# PIC32MK0128MCA048 device description
Architecture: MIPS; Family: PIC32MK; Series: PIC32MK
Registers are 32-bit, read-write, no defined reset value unless marked. A register's access mark holds for its fields unless they carry their own. Offsets are from the block's base; [hi:lo] are bit positions; 'fields as' and 'values as' point back to an identical list.

## GPIO
Instances: GPIO 0x1f860000 in periph_pb4_std
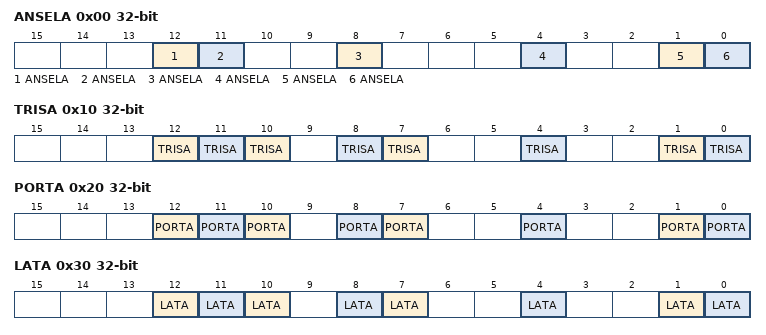
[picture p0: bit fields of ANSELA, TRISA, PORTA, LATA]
0x00 ANSELA
  [12] ANSELA, [11] ANSELA, [8] ANSELA, [4] ANSELA, [1] ANSELA, [0] ANSELA
0x10 TRISA
  [12] TRISA, [11] TRISA, [10] TRISA, [8] TRISA, [7] TRISA, [4] TRISA, [1] TRISA, [0] TRISA
0x20 PORTA
  [12] PORTA, [11] PORTA, [10] PORTA, [8] PORTA, [7] PORTA, [4] PORTA, [1] PORTA, [0] PORTA
0x30 LATA
  [12] LATA, [11] LATA, [10] LATA, [8] LATA, [7] LATA, [4] LATA, [1] LATA, [0] LATA
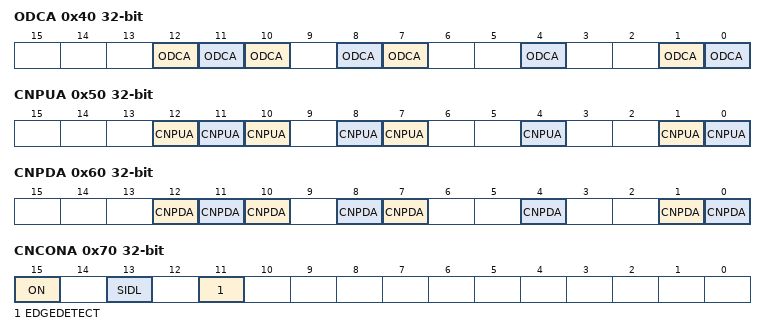
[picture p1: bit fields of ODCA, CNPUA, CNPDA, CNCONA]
0x40 ODCA
  [12] ODCA, [11] ODCA, [10] ODCA, [8] ODCA, [7] ODCA, [4] ODCA, [1] ODCA, [0] ODCA
0x50 CNPUA
  [12] CNPUA, [11] CNPUA, [10] CNPUA, [8] CNPUA, [7] CNPUA, [4] CNPUA, [1] CNPUA, [0] CNPUA
0x60 CNPDA
  [12] CNPDA, [11] CNPDA, [10] CNPDA, [8] CNPDA, [7] CNPDA, [4] CNPDA, [1] CNPDA, [0] CNPDA
0x70 CNCONA — Change Notice control for PORTx Register
  [15] ON — Change Notice Control ON bit
    1=CN is enabled; 0=CN is disabled
  [13] SIDL
  [11] EDGEDETECT — Change Notification Style bit
    1=Edge Style. Detect edge transitions (CNFx used for CN Event).; 0=Mismatch Style. Detect change from last PORTx read (CNSTATx used for CN Event).
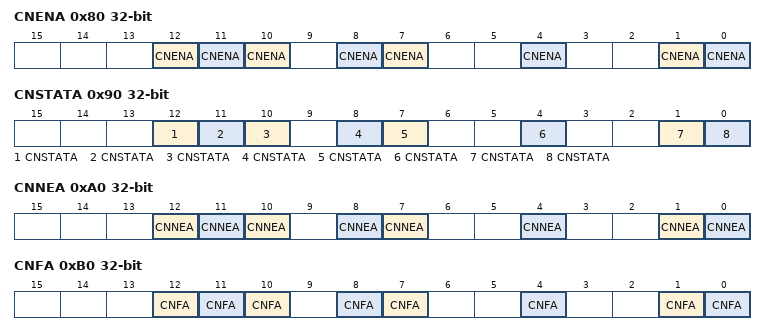
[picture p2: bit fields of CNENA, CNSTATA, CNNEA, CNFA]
0x80 CNENA
  [12] CNENA, [11] CNENA, [10] CNENA, [8] CNENA, [7] CNENA, [4] CNENA, [1] CNENA, [0] CNENA
0x90 CNSTATA
  [12] CNSTATA, [11] CNSTATA, [10] CNSTATA, [8] CNSTATA, [7] CNSTATA, [4] CNSTATA, [1] CNSTATA, [0] CNSTATA
0xA0 CNNEA
  [12] CNNEA, [11] CNNEA, [10] CNNEA, [8] CNNEA, [7] CNNEA, [4] CNNEA, [1] CNNEA, [0] CNNEA
0xB0 CNFA
  [12] CNFA, [11] CNFA, [10] CNFA, [8] CNFA, [7] CNFA, [4] CNFA, [1] CNFA, [0] CNFA
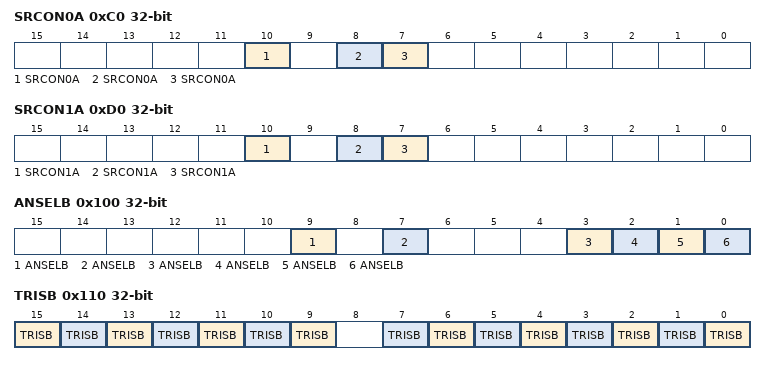
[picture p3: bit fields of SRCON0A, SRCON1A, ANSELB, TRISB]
0xC0 SRCON0A
  [10] SRCON0A, [8] SRCON0A, [7] SRCON0A
0xD0 SRCON1A
  [10] SRCON1A, [8] SRCON1A, [7] SRCON1A
0x100 ANSELB
  [9] ANSELB, [7] ANSELB, [3] ANSELB, [2] ANSELB, [1] ANSELB, [0] ANSELB
0x110 TRISB
  [15] TRISB, [14] TRISB, [13] TRISB, [12] TRISB, [11] TRISB, [10] TRISB, [9] TRISB, [7] TRISB, [6] TRISB, [5] TRISB, [4] TRISB, [3] TRISB, [2] TRISB, [1] TRISB, [0] TRISB
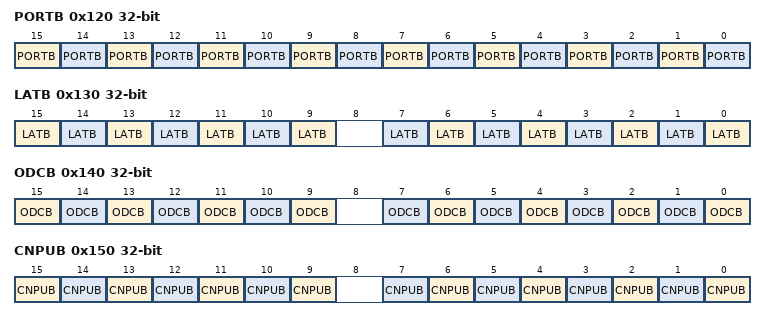
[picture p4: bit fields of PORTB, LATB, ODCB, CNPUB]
0x120 PORTB
  [15] PORTB, [14] PORTB, [13] PORTB, [12] PORTB, [11] PORTB, [10] PORTB, [9] PORTB, [8] PORTB, [7] PORTB, [6] PORTB, [5] PORTB, [4] PORTB, [3] PORTB, [2] PORTB, [1] PORTB, [0] PORTB
0x130 LATB
  [15] LATB, [14] LATB, [13] LATB, [12] LATB, [11] LATB, [10] LATB, [9] LATB, [7] LATB, [6] LATB, [5] LATB, [4] LATB, [3] LATB, [2] LATB, [1] LATB, [0] LATB
0x140 ODCB
  [15] ODCB, [14] ODCB, [13] ODCB, [12] ODCB, [11] ODCB, [10] ODCB, [9] ODCB, [7] ODCB, [6] ODCB, [5] ODCB, [4] ODCB, [3] ODCB, [2] ODCB, [1] ODCB, [0] ODCB
0x150 CNPUB
  [15] CNPUB, [14] CNPUB, [13] CNPUB, [12] CNPUB, [11] CNPUB, [10] CNPUB, [9] CNPUB, [7] CNPUB, [6] CNPUB, [5] CNPUB, [4] CNPUB, [3] CNPUB, [2] CNPUB, [1] CNPUB, [0] CNPUB
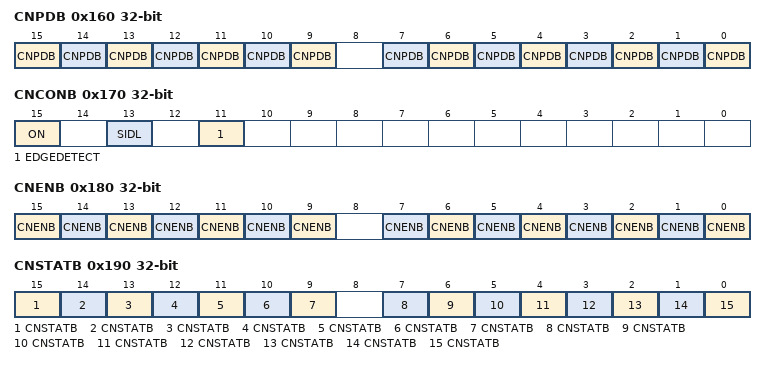
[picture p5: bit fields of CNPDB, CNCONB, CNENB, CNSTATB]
0x160 CNPDB
  [15] CNPDB, [14] CNPDB, [13] CNPDB, [12] CNPDB, [11] CNPDB, [10] CNPDB, [9] CNPDB, [7] CNPDB, [6] CNPDB, [5] CNPDB, [4] CNPDB, [3] CNPDB, [2] CNPDB, [1] CNPDB, [0] CNPDB
0x170 CNCONB — Change Notice control for PORTx Register
  fields as CNCONA
0x180 CNENB
  [15] CNENB, [14] CNENB, [13] CNENB, [12] CNENB, [11] CNENB, [10] CNENB, [9] CNENB, [7] CNENB, [6] CNENB, [5] CNENB, [4] CNENB, [3] CNENB, [2] CNENB, [1] CNENB, [0] CNENB
0x190 CNSTATB
  [15] CNSTATB, [14] CNSTATB, [13] CNSTATB, [12] CNSTATB, [11] CNSTATB, [10] CNSTATB, [9] CNSTATB, [7] CNSTATB, [6] CNSTATB, [5] CNSTATB, [4] CNSTATB, [3] CNSTATB, [2] CNSTATB, [1] CNSTATB, [0] CNSTATB
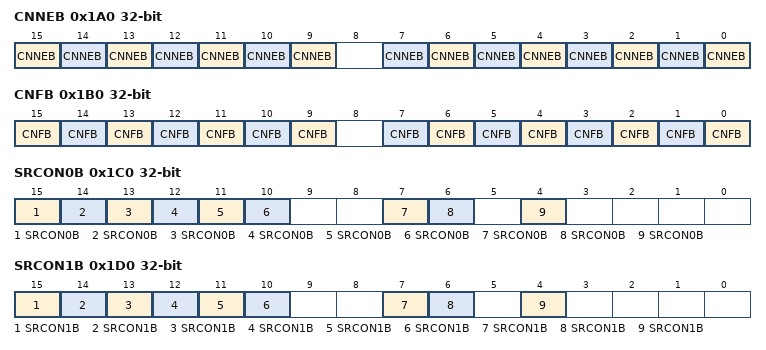
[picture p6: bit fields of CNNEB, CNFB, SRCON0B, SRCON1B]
0x1A0 CNNEB
  [15] CNNEB, [14] CNNEB, [13] CNNEB, [12] CNNEB, [11] CNNEB, [10] CNNEB, [9] CNNEB, [7] CNNEB, [6] CNNEB, [5] CNNEB, [4] CNNEB, [3] CNNEB, [2] CNNEB, [1] CNNEB, [0] CNNEB
0x1B0 CNFB
  [15] CNFB, [14] CNFB, [13] CNFB, [12] CNFB, [11] CNFB, [10] CNFB, [9] CNFB, [7] CNFB, [6] CNFB, [5] CNFB, [4] CNFB, [3] CNFB, [2] CNFB, [1] CNFB, [0] CNFB
0x1C0 SRCON0B
  [15] SRCON0B, [14] SRCON0B, [13] SRCON0B, [12] SRCON0B, [11] SRCON0B, [10] SRCON0B, [7] SRCON0B, [6] SRCON0B, [4] SRCON0B
0x1D0 SRCON1B
  [15] SRCON1B, [14] SRCON1B, [13] SRCON1B, [12] SRCON1B, [11] SRCON1B, [10] SRCON1B, [7] SRCON1B, [6] SRCON1B, [4] SRCON1B
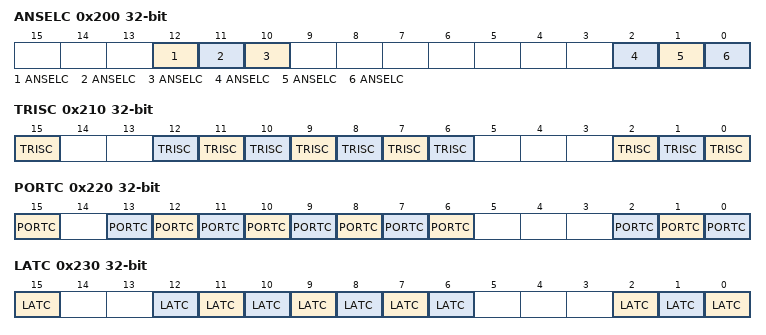
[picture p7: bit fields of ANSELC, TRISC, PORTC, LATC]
0x200 ANSELC
  [12] ANSELC, [11] ANSELC, [10] ANSELC, [2] ANSELC, [1] ANSELC, [0] ANSELC
0x210 TRISC
  [15] TRISC, [12] TRISC, [11] TRISC, [10] TRISC, [9] TRISC, [8] TRISC, [7] TRISC, [6] TRISC, [2] TRISC, [1] TRISC, [0] TRISC
0x220 PORTC
  [15] PORTC, [13] PORTC, [12] PORTC, [11] PORTC, [10] PORTC, [9] PORTC, [8] PORTC, [7] PORTC, [6] PORTC, [2] PORTC, [1] PORTC, [0] PORTC
0x230 LATC
  [15] LATC, [12] LATC, [11] LATC, [10] LATC, [9] LATC, [8] LATC, [7] LATC, [6] LATC, [2] LATC, [1] LATC, [0] LATC
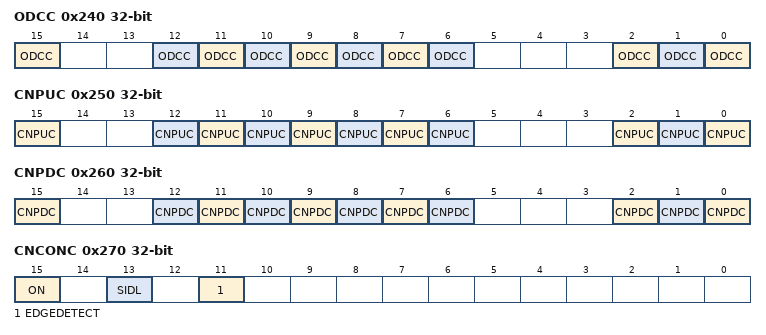
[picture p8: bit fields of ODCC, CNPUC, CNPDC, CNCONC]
0x240 ODCC
  [15] ODCC, [12] ODCC, [11] ODCC, [10] ODCC, [9] ODCC, [8] ODCC, [7] ODCC, [6] ODCC, [2] ODCC, [1] ODCC, [0] ODCC
0x250 CNPUC
  [15] CNPUC, [12] CNPUC, [11] CNPUC, [10] CNPUC, [9] CNPUC, [8] CNPUC, [7] CNPUC, [6] CNPUC, [2] CNPUC, [1] CNPUC, [0] CNPUC
0x260 CNPDC
  [15] CNPDC, [12] CNPDC, [11] CNPDC, [10] CNPDC, [9] CNPDC, [8] CNPDC, [7] CNPDC, [6] CNPDC, [2] CNPDC, [1] CNPDC, [0] CNPDC
0x270 CNCONC — Change Notice control for PORTx Register
  fields as CNCONA
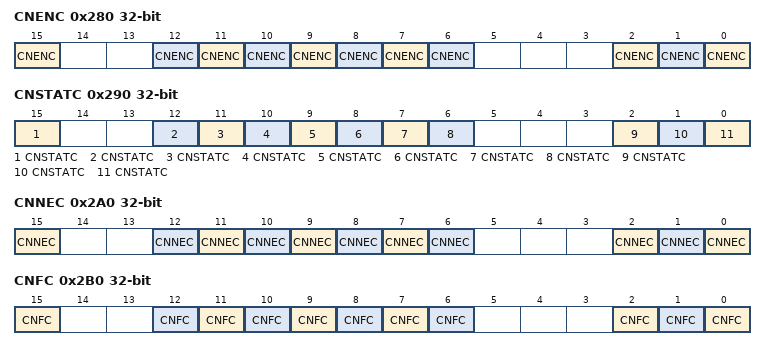
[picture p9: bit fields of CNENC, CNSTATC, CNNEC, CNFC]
0x280 CNENC
  [15] CNENC, [12] CNENC, [11] CNENC, [10] CNENC, [9] CNENC, [8] CNENC, [7] CNENC, [6] CNENC, [2] CNENC, [1] CNENC, [0] CNENC
0x290 CNSTATC
  [15] CNSTATC, [12] CNSTATC, [11] CNSTATC, [10] CNSTATC, [9] CNSTATC, [8] CNSTATC, [7] CNSTATC, [6] CNSTATC, [2] CNSTATC, [1] CNSTATC, [0] CNSTATC
0x2A0 CNNEC
  [15] CNNEC, [12] CNNEC, [11] CNNEC, [10] CNNEC, [9] CNNEC, [8] CNNEC, [7] CNNEC, [6] CNNEC, [2] CNNEC, [1] CNNEC, [0] CNNEC
0x2B0 CNFC
  [15] CNFC, [12] CNFC, [11] CNFC, [10] CNFC, [9] CNFC, [8] CNFC, [7] CNFC, [6] CNFC, [2] CNFC, [1] CNFC, [0] CNFC
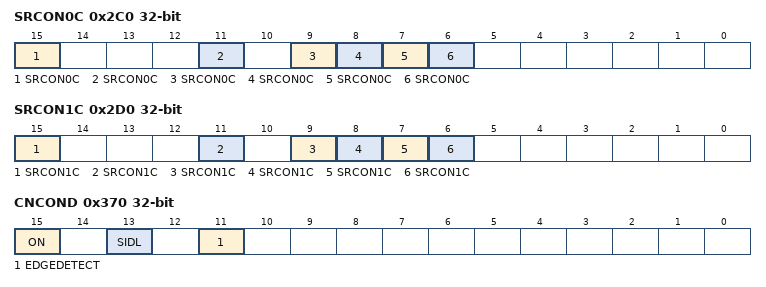
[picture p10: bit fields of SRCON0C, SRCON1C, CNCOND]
0x2C0 SRCON0C
  [15] SRCON0C, [11] SRCON0C, [9] SRCON0C, [8] SRCON0C, [7] SRCON0C, [6] SRCON0C
0x2D0 SRCON1C
  [15] SRCON1C, [11] SRCON1C, [9] SRCON1C, [8] SRCON1C, [7] SRCON1C, [6] SRCON1C
0x300 ANSELD
0x310 TRISD
  [8] TRISD
0x320 PORTD
  [8] PORTD
0x330 LATD
  [8] LATD
0x340 ODCD
  [8] ODCD
0x350 CNPUD
  [8] CNPUD
0x360 CNPDD
  [8] CNPDD
0x370 CNCOND — Change Notice control for PORTx Register
  fields as CNCONA
0x380 CNEND
  [8] CNEND
0x390 CNSTATD
  [8] CNSTATD
0x3A0 CNNED
  [8] CNNED
0x3B0 CNFD
  [8] CNFD
0x3C0 SRCON0D
  [8] SRCON0D
0x3D0 SRCON1D
  [8] SRCON1D
